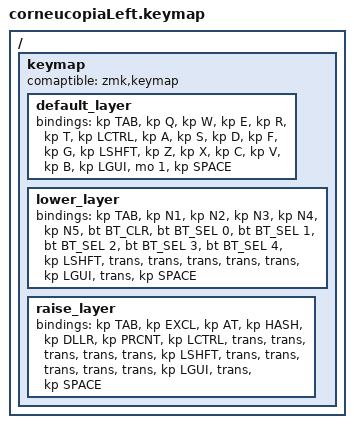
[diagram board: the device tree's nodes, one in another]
#include <behaviors.dtsi>
#include <dt-bindings/zmk/keys.h>
#include <dt-bindings/zmk/bt.h>

/ {
    keymap {
        comaptible = "zmk,keymap";

        default_layer {
            // -----------------------------------------------------------------------------------------
            // |  TAB |  Q  |  W  |  E  |  R  |  T  |
            // | CTRL |  A  |  S  |  D  |  F  |  G  |
            // | SHFT |  Z  |  X  |  C  |  V  |  B  |
            //                    | GUI | LWR | SPC |
                                    bindings = <
            &kp TAB   &kp Q &kp W &kp E &kp R &kp T
            &kp LCTRL &kp A &kp S &kp D &kp F &kp G
            &kp LSHFT &kp Z &kp X &kp C &kp V &kp B
                            &kp LGUI &mo 1 &kp SPACE
                                    >;
        };

        lower_layer {
            // -----------------------------------------------------------------------------------------
            // |  TAB |  1  |  2  |  3  |  4  |  5  |
            // | BTCLR| BT1 | BT2 | BT3 | BT4 | BT5 |
            // | SHFT |     |     |     |     |     |
            //                    | GUI |     | SPC |
                                    bindings = <
            &kp TAB    &kp N1       &kp N2       &kp N3       &kp N4       &kp N5
            &bt BT_CLR &bt BT_SEL 0 &bt BT_SEL 1 &bt BT_SEL 2 &bt BT_SEL 3 &bt BT_SEL 4
            &kp LSHFT  &trans       &trans       &trans       &trans       &trans
                                                &kp LGUI     &trans       &kp SPACE
                                    >;
        };

        raise_layer {
            // -----------------------------------------------------------------------------------------
            // |  TAB |  !  |  @  |  #  |  $  |  %  |
            // | CTRL |     |     |     |     |     |
            // | SHFT |     |     |     |     |     |
            //                    | GUI |     | SPC |
                                    bindings = <
            &kp  TAB  &kp EXCL &kp AT &kp HASH &kp DLLR &kp PRCNT
            &kp LCTRL &trans   &trans &trans   &trans   &trans
            &kp LSHFT &trans   &trans &trans   &trans   &trans
                                        &kp LGUI &trans   &kp SPACE
                                    >;
        };

    }
}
